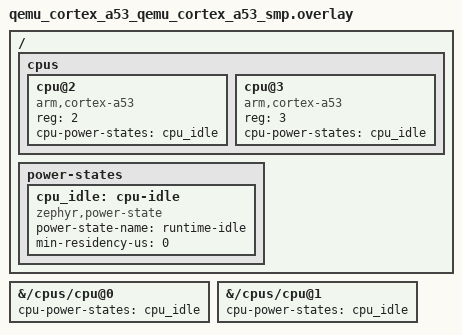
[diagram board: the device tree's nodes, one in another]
/* Copyright 2022 Carlo Caione <ccaione@baylibre.com>
 * SPDX-License-Identifier: Apache-2.0
 */

/ {
	cpus {
		cpu@2 {
			compatible = "arm,cortex-a53";
			reg = <2>;
			device_type = "cpu";
		};

		cpu@3 {
			compatible = "arm,cortex-a53";
			reg = <3>;
			device_type = "cpu";
		};
	};
};

/* Taken only by the PM scenario, which provides the PM hooks. */
/ {
	power-states {
		cpu_idle: cpu-idle {
			compatible = "zephyr,power-state";
			power-state-name = "runtime-idle";
			min-residency-us = <0>;
		};
	};
};

&{/cpus/cpu@0} {
	cpu-power-states = <&cpu_idle>;
};

&{/cpus/cpu@1} {
	cpu-power-states = <&cpu_idle>;
};

&{/cpus/cpu@2} {
	cpu-power-states = <&cpu_idle>;
};

&{/cpus/cpu@3} {
	cpu-power-states = <&cpu_idle>;
};
